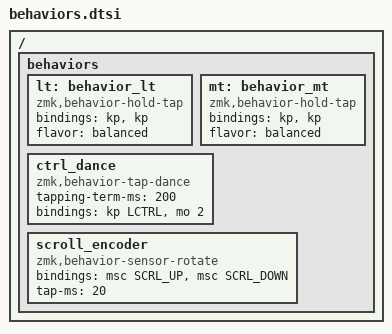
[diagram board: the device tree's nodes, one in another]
/ {
    behaviors {
        lt: behavior_lt {
            compatible = "zmk,behavior-hold-tap";
            #binding-cells = <2>;
            bindings = <&kp>, <&kp>;
            flavor = "balanced";
        };
        
        mt: behavior_mt {
            compatible = "zmk,behavior-hold-tap";
            #binding-cells = <2>;
            bindings = <&kp>, <&kp>;
            flavor = "balanced";
        };

        ctrl_dance: ctrl_dance {
            compatible = "zmk,behavior-tap-dance";
            #binding-cells = <0>;
            tapping-term-ms = <200>;  
            bindings = <&kp LCTRL>, <&mo 2>;  
        };        
        // hm_l: homerow_mods_left {
        //     compatible = "zmk,behavior-hold-tap";
        //     #binding-cells = <2>;
        //     bindings = <&kp>, <&kp>;

        //     flavor = "balanced";
        //     tapping-term-ms = <HM_TAPPING_TERM>;
        //     quick-tap-ms = <HM_TAPPING_TERM_FAST>;
        //     require-prior-idle-ms = <HM_PRIOR_IDLE>;
        //     hold-trigger-key-positions = <KEYS_R KEYS_T>;
        //     hold-trigger-on-release;
        // };

        // hm_r: homerow_mods_right {
        //     compatible = "zmk,behavior-hold-tap";
        //     #binding-cells = <2>;
        //     bindings = <&kp>, <&kp>;

        //     flavor = "balanced";
        //     tapping-term-ms = <HM_TAPPING_TERM>;
        //     quick-tap-ms = <HM_TAPPING_TERM_FAST>;
        //     require-prior-idle-ms = <HM_PRIOR_IDLE>;
        //     hold-trigger-key-positions = <KEYS_L KEYS_T>;
        //     hold-trigger-on-release;
        // };

        scroll_encoder: scroll_encoder {
            compatible = "zmk,behavior-sensor-rotate";
            #sensor-binding-cells = <0>;
            bindings = <&msc SCRL_UP>, <&msc SCRL_DOWN>;
            tap-ms = <20>;
        };
    };
};
